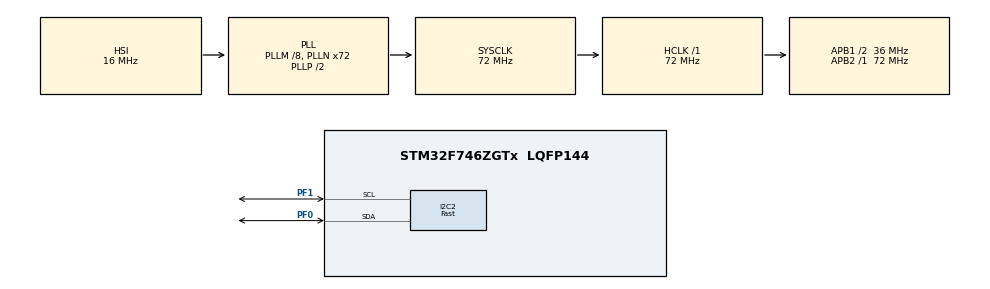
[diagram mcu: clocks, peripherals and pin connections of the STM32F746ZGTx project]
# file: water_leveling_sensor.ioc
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I2C2.I2C_Fall_Time=300
I2C2.I2C_Rise_Time=300
I2C2.I2C_Speed_Mode=I2C_Fast
I2C2.Timing=0x00E6112B
Mcu.Family=STM32F7
Mcu.Name=STM32F746ZGTx
Mcu.Package=LQFP144
NVIC.I2C2_ER_IRQn=true\:0\:0\:false\:false\:true\:true\:true
NVIC.I2C2_EV_IRQn=true\:0\:0\:false\:false\:true\:true\:true
NVIC.PriorityGroup=NVIC_PRIORITYGROUP_4
PC14/OSC32_IN.Mode=LSE-External-Oscillator
PC14/OSC32_IN.Signal=RCC_OSC32_IN
PC15/OSC32_OUT.Mode=LSE-External-Oscillator
PC15/OSC32_OUT.Signal=RCC_OSC32_OUT
PF0.Mode=I2C
PF0.Signal=I2C2_SDA
PF1.Mode=I2C
PF1.Signal=I2C2_SCL
PH0/OSC_IN.Mode=HSE-External-Oscillator
PH0/OSC_IN.Signal=RCC_OSC_IN
PH1/OSC_OUT.Mode=HSE-External-Oscillator
PH1/OSC_OUT.Signal=RCC_OSC_OUT
ProjectManager.HeapSize=0x200
ProjectManager.StackSize=0x400
ProjectManager.TargetToolchain=MDK-ARM V5
RCC.48MHZClocksFreq_Value=24000000
RCC.AHBFreq_Value=72000000
RCC.APB1CLKDivider=RCC_HCLK_DIV2
RCC.APB1Freq_Value=36000000
RCC.APB1TimFreq_Value=72000000
RCC.APB2Freq_Value=72000000
RCC.APB2TimFreq_Value=72000000
RCC.CortexFreq_Value=72000000
RCC.HCLKFreq_Value=72000000
RCC.HSE_VALUE=8000000
RCC.HSI_VALUE=16000000
RCC.PLLM=8
RCC.PLLMUL=RCC_PLL_MUL9
RCC.PLLN=72
RCC.PLLQ=3
RCC.PRESCALERUSB=RCC_USBCLKSOURCE_PLL_DIV1_5
RCC.SYSCLKFreq_VALUE=72000000
RCC.SYSCLKSource=RCC_SYSCLKSOURCE_PLLCLK
RCC.SYSCLKSourceVirtual=RCC_SYSCLKSOURCE_PLLCLK
RCC.USBFreq_Value=48000000
RCC.VCOOutputFreq_Value=144000000
board=NUCLEO-F746ZG

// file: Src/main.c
/* USER CODE BEGIN Header */
/**
  ******************************************************************************
  * @file           : main.c
  * @brief          : Main program body
  ******************************************************************************
  * @attention
  *
  * <h2><center>&copy; Copyright (c) 2021 STMicroelectronics.
  * All rights reserved.</center></h2>
  *
  * This software component is licensed by ST under BSD 3-Clause license,
  * the "License"; You may not use this file except in compliance with the
  * License. You may obtain a copy of the License at:
  *                        opensource.org/licenses/BSD-3-Clause
  *
  ******************************************************************************
  */
/* USER CODE END Header */

#include "main.h"

/* USER CODE BEGIN Includes */
#include "string.h"
/* USER CODE END Includes */

I2C_HandleTypeDef hi2c2;

/* USER CODE BEGIN PV */
uint8_t buf_l[8]={0};
uint8_t buf_h[12]={0};
uint8_t low_data[8]={0};
uint8_t high_data[12]={0};

/* USER CODE END PV */

void SystemClock_Config(void);
static void MX_GPIO_Init(void);
static void MX_I2C2_Init(void);

int main(void)
{
  /* USER CODE BEGIN 1 */
	volatile HAL_StatusTypeDef error;
  /* USER CODE END 1 */

  /* MCU Configuration--------------------------------------------------------*/

  /* Reset of all peripherals, Initializes the Flash interface and the Systick. */
  HAL_Init();

  /* Configure the system clock */
  SystemClock_Config();

  /* Initialize all configured peripherals */
  MX_GPIO_Init();
  MX_I2C2_Init();

  /* Infinite loop */
  /* USER CODE BEGIN WHILE */
  while (1)
  {
		memset(buf_h,0,sizeof(buf_h));
		memset(buf_l,0,sizeof(buf_l));

		//high raw data
		error = HAL_I2C_Master_Transmit(&hi2c2, 0x78 << 1, buf_h, sizeof(buf_h), 100);
		if(error==HAL_OK)
		{
			error = HAL_I2C_Master_Receive(&hi2c2, 0x78 << 1, high_data, 12, 500);
			if(error!=HAL_OK){} //TODO Error Handling
		}

		//low raw data
		error = HAL_I2C_Master_Transmit(&hi2c2, 0x77 << 1, buf_l, sizeof(buf_l), 100);
		if(error==HAL_OK)
		{
			error = HAL_I2C_Master_Receive(&hi2c2, 0x77 << 1, low_data, 8, 500);
			if(error!=HAL_OK){} //TODO Error Handling
		}

		/* USER CODE END WHILE */

  }
}

void SystemClock_Config(void)
{
  RCC_OscInitTypeDef RCC_OscInitStruct = {0};
  RCC_ClkInitTypeDef RCC_ClkInitStruct = {0};
  RCC_PeriphCLKInitTypeDef PeriphClkInitStruct = {0};

  /** Configure LSE Drive Capability
  */
  HAL_PWR_EnableBkUpAccess();
  /** Configure the main internal regulator output voltage
  */
  __HAL_RCC_PWR_CLK_ENABLE();
  __HAL_PWR_VOLTAGESCALING_CONFIG(PWR_REGULATOR_VOLTAGE_SCALE3);
  /** Initializes the CPU, AHB and APB busses clocks
  */
  RCC_OscInitStruct.OscillatorType = RCC_OSCILLATORTYPE_HSI;
  RCC_OscInitStruct.HSIState = RCC_HSI_ON;
  RCC_OscInitStruct.HSICalibrationValue = RCC_HSICALIBRATION_DEFAULT;
  RCC_OscInitStruct.PLL.PLLState = RCC_PLL_ON;
  RCC_OscInitStruct.PLL.PLLSource = RCC_PLLSOURCE_HSI;
  RCC_OscInitStruct.PLL.PLLM = 8;
  RCC_OscInitStruct.PLL.PLLN = 72;
  RCC_OscInitStruct.PLL.PLLP = RCC_PLLP_DIV2;
  RCC_OscInitStruct.PLL.PLLQ = 3;
  if (HAL_RCC_OscConfig(&RCC_OscInitStruct) != HAL_OK)
  {
    Error_Handler();
  }
  /** Initializes the CPU, AHB and APB busses clocks
  */
  RCC_ClkInitStruct.ClockType = RCC_CLOCKTYPE_HCLK|RCC_CLOCKTYPE_SYSCLK
                              |RCC_CLOCKTYPE_PCLK1|RCC_CLOCKTYPE_PCLK2;
  RCC_ClkInitStruct.SYSCLKSource = RCC_SYSCLKSOURCE_PLLCLK;
  RCC_ClkInitStruct.AHBCLKDivider = RCC_SYSCLK_DIV1;
  RCC_ClkInitStruct.APB1CLKDivider = RCC_HCLK_DIV2;
  RCC_ClkInitStruct.APB2CLKDivider = RCC_HCLK_DIV1;

  if (HAL_RCC_ClockConfig(&RCC_ClkInitStruct, FLASH_LATENCY_2) != HAL_OK)
  {
    Error_Handler();
  }
  PeriphClkInitStruct.PeriphClockSelection = RCC_PERIPHCLK_I2C2;
  PeriphClkInitStruct.I2c2ClockSelection = RCC_I2C2CLKSOURCE_PCLK1;
  if (HAL_RCCEx_PeriphCLKConfig(&PeriphClkInitStruct) != HAL_OK)
  {
    Error_Handler();
  }
}

static void MX_I2C2_Init(void)
{

  hi2c2.Instance = I2C2;
  hi2c2.Init.Timing = 0x00E6112B;
  hi2c2.Init.OwnAddress1 = 0;
  hi2c2.Init.AddressingMode = I2C_ADDRESSINGMODE_7BIT;
  hi2c2.Init.DualAddressMode = I2C_DUALADDRESS_DISABLE;
  hi2c2.Init.OwnAddress2 = 0;
  hi2c2.Init.OwnAddress2Masks = I2C_OA2_NOMASK;
  hi2c2.Init.GeneralCallMode = I2C_GENERALCALL_DISABLE;
  hi2c2.Init.NoStretchMode = I2C_NOSTRETCH_DISABLE;
  if (HAL_I2C_Init(&hi2c2) != HAL_OK)
  {
    Error_Handler();
  }
  /** Configure Analogue filter
  */
  if (HAL_I2CEx_ConfigAnalogFilter(&hi2c2, I2C_ANALOGFILTER_ENABLE) != HAL_OK)
  {
    Error_Handler();
  }
  /** Configure Digital filter
  */
  if (HAL_I2CEx_ConfigDigitalFilter(&hi2c2, 0) != HAL_OK)
  {
    Error_Handler();
  }

}

static void MX_GPIO_Init(void)
{

  /* GPIO Ports Clock Enable */
  __HAL_RCC_GPIOC_CLK_ENABLE();
  __HAL_RCC_GPIOF_CLK_ENABLE();
  __HAL_RCC_GPIOH_CLK_ENABLE();

}

void Error_Handler(void)
{
}

/************************ (C) COPYRIGHT STMicroelectronics *****END OF FILE****/
